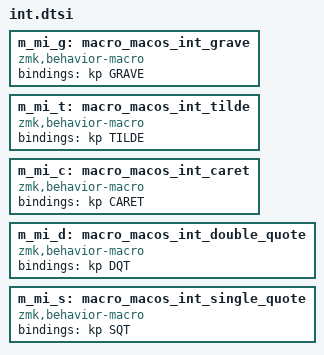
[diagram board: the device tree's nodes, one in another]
// action:  `
m_mi_g: macro_macos_int_grave {
    compatible = "zmk,behavior-macro";
    #binding-cells = <0>;
    bindings =
        <&kp GRAVE>;
};

// action:  ~
m_mi_t: macro_macos_int_tilde {
    compatible = "zmk,behavior-macro";
    #binding-cells = <0>;
    bindings =
        <&kp TILDE>;
};

// action:  ^
m_mi_c: macro_macos_int_caret {
    compatible = "zmk,behavior-macro";
    #binding-cells = <0>;
    bindings =
        <&kp CARET>;
};

// action:  "
m_mi_d: macro_macos_int_double_quote {
    compatible = "zmk,behavior-macro";
    #binding-cells = <0>;
    bindings =
        <&kp DQT>;
};

// action:  '
m_mi_s: macro_macos_int_single_quote {
    compatible = "zmk,behavior-macro";
    #binding-cells = <0>;
    bindings =
        <&kp SQT>;
};
